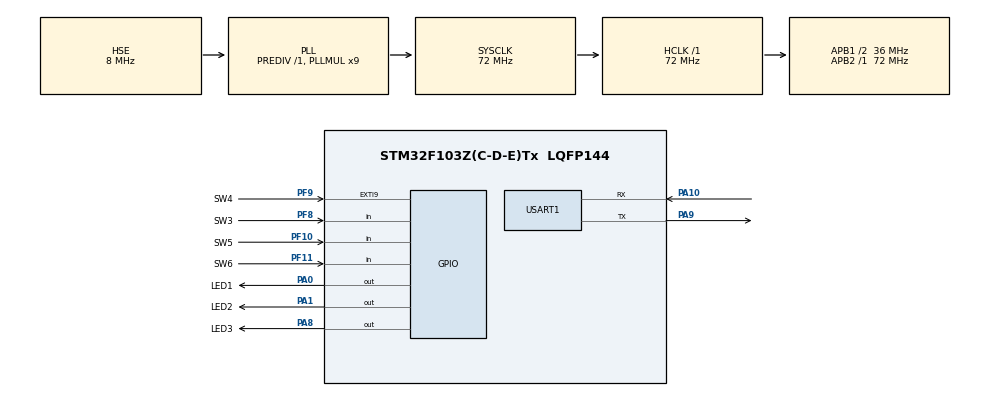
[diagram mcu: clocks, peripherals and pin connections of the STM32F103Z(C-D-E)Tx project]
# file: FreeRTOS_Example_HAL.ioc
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Mcu.Family=STM32F1
Mcu.Name=STM32F103Z(C-D-E)Tx
Mcu.Package=LQFP144
NVIC.EXTI9_5_IRQn=true\:6\:0\:true\:false\:true\:true\:true\:true
NVIC.PriorityGroup=NVIC_PRIORITYGROUP_4
NVIC.TIM2_IRQn=true\:4\:0\:true\:false\:true\:true\:true\:true
NVIC.TIM3_IRQn=true\:6\:0\:true\:false\:true\:true\:true\:true
NVIC.TIM6_IRQn=true\:0\:0\:true\:false\:true\:false\:true\:true
NVIC.TimeBase=TIM6_IRQn
NVIC.TimeBaseIP=TIM6
OSC_IN.Mode=HSE-External-Oscillator
OSC_IN.Signal=RCC_OSC_IN
OSC_OUT.Mode=HSE-External-Oscillator
OSC_OUT.Signal=RCC_OSC_OUT
PA0-WKUP.GPIO_Label=LED1
PA0-WKUP.GPIO_Speed=GPIO_SPEED_FREQ_HIGH
PA0-WKUP.PinState=GPIO_PIN_SET
PA0-WKUP.Signal=GPIO_Output
PA1.GPIO_Label=LED2
PA1.GPIO_Speed=GPIO_SPEED_FREQ_HIGH
PA1.PinState=GPIO_PIN_SET
PA1.Signal=GPIO_Output
PA10.Mode=Asynchronous
PA10.Signal=USART1_RX
PA13.Mode=Serial_Wire
PA13.Signal=SYS_JTMS-SWDIO
PA14.Mode=Serial_Wire
PA14.Signal=SYS_JTCK-SWCLK
PA8.GPIO_Label=LED3
PA8.GPIO_Speed=GPIO_SPEED_FREQ_HIGH
PA8.PinState=GPIO_PIN_SET
PA8.Signal=GPIO_Output
PA9.Mode=Asynchronous
PA9.Signal=USART1_TX
PC14-OSC32_IN.Mode=LSE-External-Oscillator
PC14-OSC32_IN.Signal=RCC_OSC32_IN
PC15-OSC32_OUT.Mode=LSE-External-Oscillator
PC15-OSC32_OUT.Signal=RCC_OSC32_OUT
PF10.GPIO_Label=SW5
PF10.GPIO_PuPd=GPIO_PULLDOWN
PF10.Signal=GPIO_Input
PF11.GPIO_Label=SW6
PF11.GPIO_PuPd=GPIO_PULLDOWN
PF11.Signal=GPIO_Input
PF8.GPIO_Label=SW3
PF8.GPIO_PuPd=GPIO_PULLUP
PF8.Signal=GPIO_Input
PF9.GPIO_Label=SW4
PF9.GPIO_ModeDefaultEXTI=GPIO_MODE_IT_FALLING
PF9.GPIO_PuPd=GPIO_PULLUP
PF9.Signal=GPXTI9
ProjectManager.HeapSize=0x200
ProjectManager.StackSize=0x400
ProjectManager.TargetToolchain=MDK-ARM V5.32
RCC.AHBFreq_Value=72000000
RCC.APB1CLKDivider=RCC_HCLK_DIV2
RCC.APB1Freq_Value=36000000
RCC.APB1TimFreq_Value=72000000
RCC.APB2Freq_Value=72000000
RCC.APB2TimFreq_Value=72000000
RCC.HCLKFreq_Value=72000000
RCC.PLLMUL=RCC_PLL_MUL9
RCC.PLLSourceVirtual=RCC_PLLSOURCE_HSE
RCC.SYSCLKFreq_VALUE=72000000
RCC.SYSCLKSource=RCC_SYSCLKSOURCE_PLLCLK
RCC.USBFreq_Value=72000000
TIM2.Period=9999
TIM2.Prescaler=7199
TIM3.Period=9999
TIM3.Prescaler=7199
USART1.VirtualMode=VM_ASYNC
VP_SYS_VS_tim6.Mode=TIM6
VP_TIM2_VS_ClockSourceINT.Mode=Internal
VP_TIM3_VS_ClockSourceINT.Mode=Internal
board=custom

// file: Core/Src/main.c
/* USER CODE BEGIN Header */
/**
  ******************************************************************************
  * @file           : main.c
  * @brief          : Main program body
  ******************************************************************************
  * @attention
  *
  * Copyright (c) 2025 STMicroelectronics.
  * All rights reserved.
  *
  * This software is licensed under terms that can be found in the LICENSE file
  * in the root directory of this software component.
  * If no LICENSE file comes with this software, it is provided AS-IS.
  *
  ******************************************************************************
  */
/* USER CODE END Header */
#include "main.h"
#include "tim.h"
#include "usart.h"
#include "gpio.h"

/* USER CODE BEGIN Includes */

#include "App_FreeRTOS.h"

/* USER CODE END Includes */

void SystemClock_Config(void);

int main(void)
{

  /* MCU Configuration--------------------------------------------------------*/

  /* Reset of all peripherals, Initializes the Flash interface and the Systick. */
  HAL_Init();

  /* Configure the system clock */
  SystemClock_Config();

  /* Initialize all configured peripherals */
  MX_GPIO_Init();
  MX_USART1_UART_Init();
  MX_TIM2_Init();
  MX_TIM3_Init();
  /* USER CODE BEGIN 2 */

  printf("FreeRTOS Example Start: \n");

  // 启动TIM2并开启中断
  HAL_TIM_Base_Start_IT(&htim2);
  // 启动TIM3并开启中断
  HAL_TIM_Base_Start_IT(&htim3);

  // 启动FreeRTOS
  App_FreeRTOS_Start();

  // 后面的语句将不会执行
  printf("FreeRTOS Example End: \n");

  /* USER CODE END 2 */

  /* Infinite loop */
  while (1)
  {

  }
}

void SystemClock_Config(void)
{
  RCC_OscInitTypeDef RCC_OscInitStruct = {0};
  RCC_ClkInitTypeDef RCC_ClkInitStruct = {0};

  /** Initializes the RCC Oscillators according to the specified parameters
  * in the RCC_OscInitTypeDef structure.
  */
  RCC_OscInitStruct.OscillatorType = RCC_OSCILLATORTYPE_HSE;
  RCC_OscInitStruct.HSEState = RCC_HSE_ON;
  RCC_OscInitStruct.HSEPredivValue = RCC_HSE_PREDIV_DIV1;
  RCC_OscInitStruct.HSIState = RCC_HSI_ON;
  RCC_OscInitStruct.PLL.PLLState = RCC_PLL_ON;
  RCC_OscInitStruct.PLL.PLLSource = RCC_PLLSOURCE_HSE;
  RCC_OscInitStruct.PLL.PLLMUL = RCC_PLL_MUL9;
  if (HAL_RCC_OscConfig(&RCC_OscInitStruct) != HAL_OK)
  {
    Error_Handler();
  }

  /** Initializes the CPU, AHB and APB buses clocks
  */
  RCC_ClkInitStruct.ClockType = RCC_CLOCKTYPE_HCLK|RCC_CLOCKTYPE_SYSCLK
                              |RCC_CLOCKTYPE_PCLK1|RCC_CLOCKTYPE_PCLK2;
  RCC_ClkInitStruct.SYSCLKSource = RCC_SYSCLKSOURCE_PLLCLK;
  RCC_ClkInitStruct.AHBCLKDivider = RCC_SYSCLK_DIV1;
  RCC_ClkInitStruct.APB1CLKDivider = RCC_HCLK_DIV2;
  RCC_ClkInitStruct.APB2CLKDivider = RCC_HCLK_DIV1;

  if (HAL_RCC_ClockConfig(&RCC_ClkInitStruct, FLASH_LATENCY_2) != HAL_OK)
  {
    Error_Handler();
  }
}

void HAL_TIM_PeriodElapsedCallback(TIM_HandleTypeDef *htim)
{
  if (htim->Instance == TIM6) {
    HAL_IncTick();
  }
  /* USER CODE BEGIN Callback 1 */

  // 如果是 TIM2 的更新中断
  if (htim->Instance == TIM2)
  {
    printf("\nTIM2 Update Interrupt, 优先级是4 .... \n");
  }

  // 如果是 TIM3 的更新中断
  if (htim->Instance == TIM3)
  {
    printf("\nTIM3 Update Interrupt, 优先级是6 .... \n");
  }

  /* USER CODE END Callback 1 */
}

void Error_Handler(void)
{
  __disable_irq();
  while (1)
  {
  }
}
